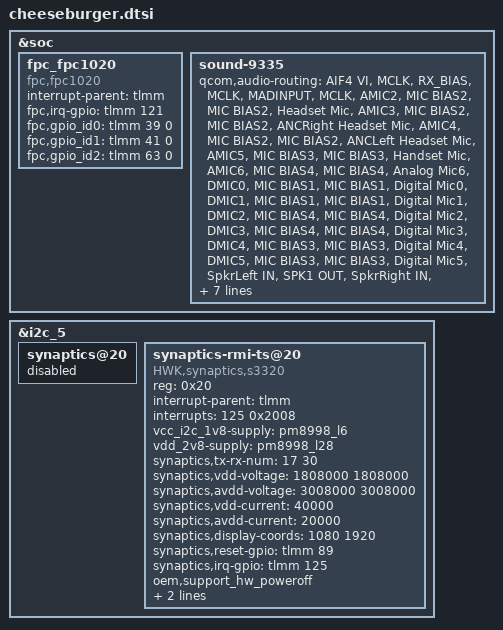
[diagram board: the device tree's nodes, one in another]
/* Copyright (c) 2016-2017, The Linux Foundation. All rights reserved.
 *
 * This program is free software; you can redistribute it and/or modify
 * it under the terms of the GNU General Public License version 2 and
 * only version 2 as published by the Free Software Foundation.
 *
 * This program is distributed in the hope that it will be useful,
 * but WITHOUT ANY WARRANTY; without even the implied warranty of
 * MERCHANTABILITY or FITNESS FOR A PARTICULAR PURPOSE.  See the
 * GNU General Public License for more details.
 */

#include "oneplus5-common.dtsi"

/* I/O */
&soc {

	/* Fingerprint */
	fpc_fpc1020 {
		compatible = "fpc,fpc1020";
		interrupt-parent = <&tlmm>;
		fpc,irq-gpio    = <&tlmm 121 0>;
		fpc,gpio_id0    = <&tlmm 39 0>;
		fpc,gpio_id1    = <&tlmm 41 0>;
		fpc,gpio_id2    = <&tlmm 63 0>;
	};

};

/* Display */
&i2c_5 {
	synaptics@20 {
		status = "disabled";
	};
	synaptics-rmi-ts@20 {
		compatible = "HWK,synaptics,s3320";
		reg = <0x20>;
		interrupt-parent = <&tlmm>;
		interrupts = <125 0x2008>;
		vcc_i2c_1v8-supply = <&pm8998_l6>;
		vdd_2v8-supply = <&pm8998_l28>;
		synaptics,tx-rx-num = <17 30>;
		synaptics,vdd-voltage = <1808000 1808000>;
		synaptics,avdd-voltage = <3008000 3008000>;
		synaptics,vdd-current = <40000>;
		synaptics,avdd-current = <20000>;
		synaptics,display-coords = <1080 1920>;
		synaptics,reset-gpio = <&tlmm 89 0x00>;
		synaptics,irq-gpio = <&tlmm 125 0x2008>;
		oem,support_hw_poweroff;
		pinctrl-names = "pmx_ts_active", "pmx_ts_suspend";
		pinctrl-0 = <&ts_active>;
		pinctrl-1 = <&ts_int_suspend &ts_reset_suspend>;
	};
};

/* Audio */
&soc {
	sound-9335 {
		qcom,audio-routing =
			"AIF4 VI", "MCLK",
			"RX_BIAS", "MCLK",
			"MADINPUT", "MCLK",
			"AMIC2", "MIC BIAS2",
			"MIC BIAS2", "Headset Mic",
			"AMIC3", "MIC BIAS2",
			"MIC BIAS2", "ANCRight Headset Mic",
			"AMIC4", "MIC BIAS2",
			"MIC BIAS2", "ANCLeft Headset Mic",
			"AMIC5", "MIC BIAS3",
			"MIC BIAS3", "Handset Mic",
			"AMIC6", "MIC BIAS4",
			"MIC BIAS4", "Analog Mic6",
			"DMIC0", "MIC BIAS1",
			"MIC BIAS1", "Digital Mic0",
			"DMIC1", "MIC BIAS1",
			"MIC BIAS1", "Digital Mic1",
			"DMIC2", "MIC BIAS4",
			"MIC BIAS4", "Digital Mic2",
			"DMIC3", "MIC BIAS4",
			"MIC BIAS4", "Digital Mic3",
			"DMIC4", "MIC BIAS3",
			"MIC BIAS3", "Digital Mic4",
			"DMIC5", "MIC BIAS3",
			"MIC BIAS3", "Digital Mic5",
			"SpkrLeft IN", "SPK1 OUT",
			"SpkrRight IN", "SPK2 OUT";
		qcom,us-euro-gpios = <>;
		qcom,msm-mbhc-hphl-swh = <1>;
		qcom,msm-mbhc-gnd-swh = <1>;
		qcom,wsa-max-devs = <0>;
		qcom,wsa-devs = <0>;
		qcom,wsa-aux-dev-prefix = <0>;
	};
};
